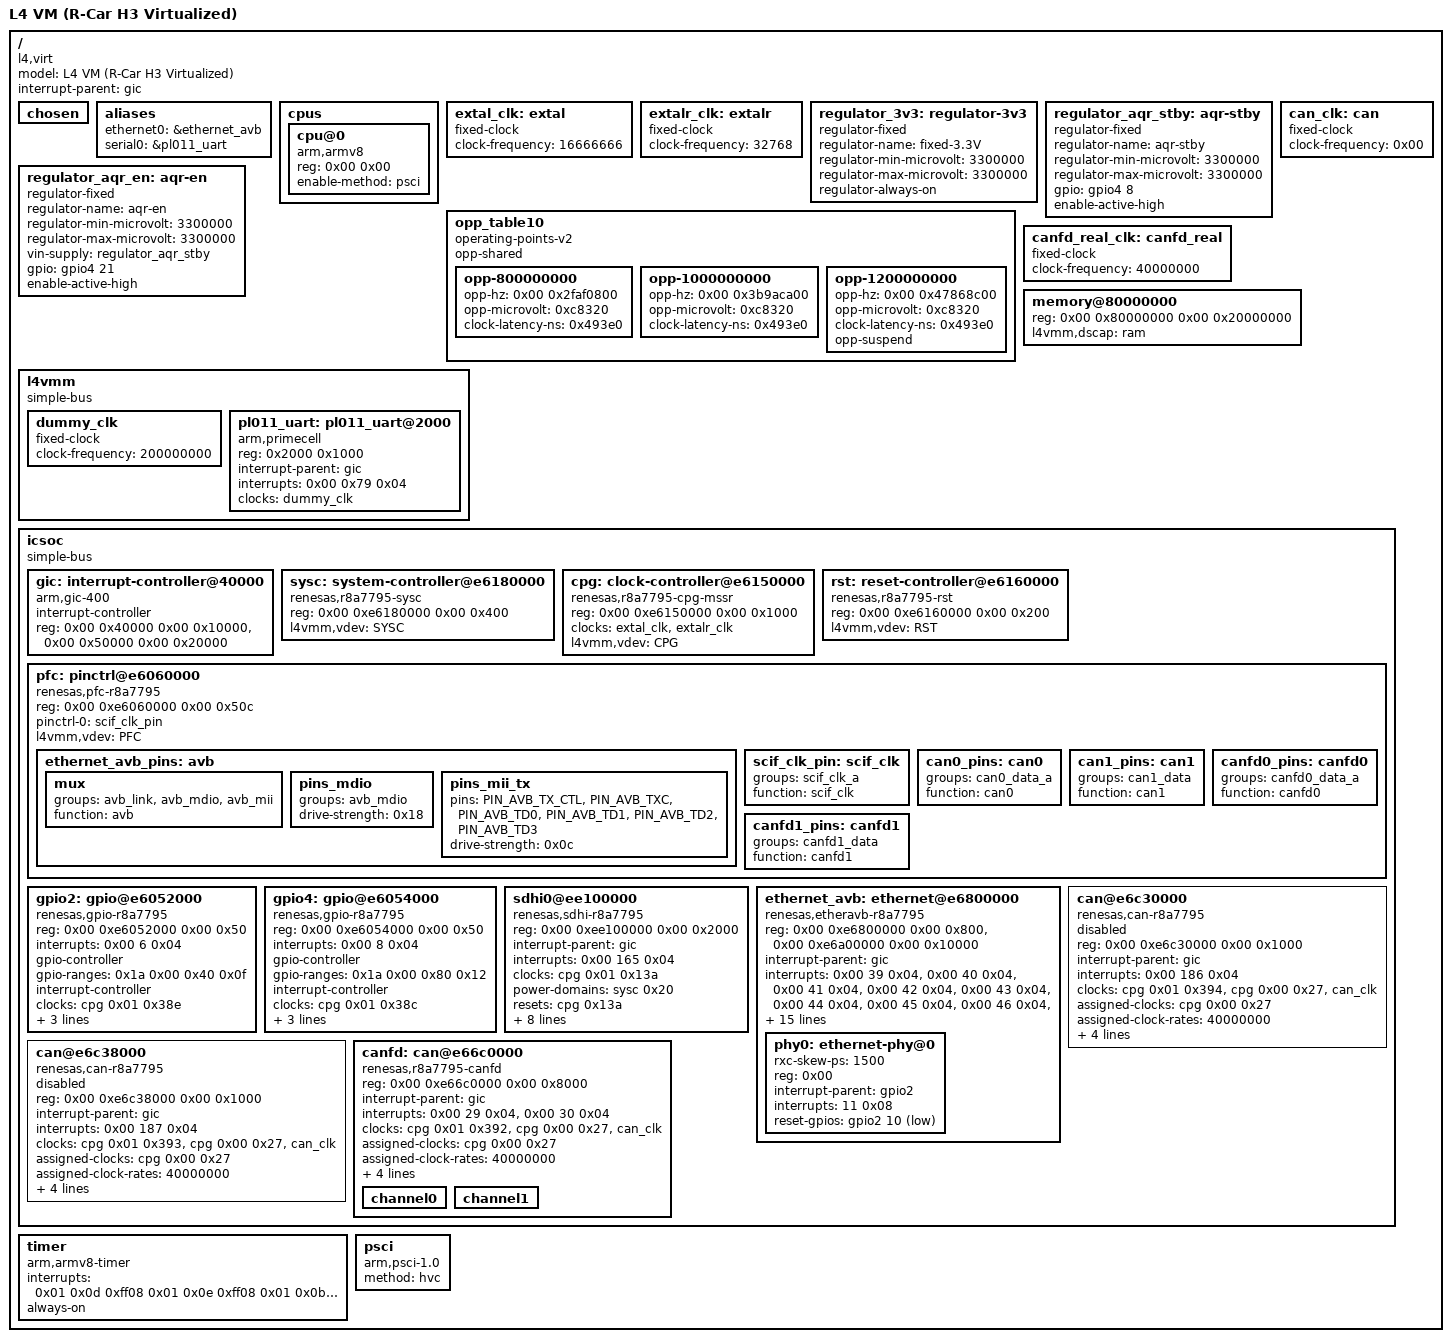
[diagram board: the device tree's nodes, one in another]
/dts-v1/;

/ {
	#address-cells = <0x02>;
	#size-cells = <0x02>;
	model = "L4 VM (R-Car H3 Virtualized)";
	/* CRITICAL: Added native R-Car strings so Renesas drivers load their pin tables */
	compatible = "l4,virt", "linux,dummy-virt", "shimafuji,kingfisher", "renesas,h3ulcb", "renesas,r8a7795";
	interrupt-parent = <&gic>;

	chosen {};
	aliases {
		ethernet0 = &ethernet_avb;
		serial0 = &pl011_uart;
	};

	cpus {
		#address-cells = <0x02>;
		#size-cells = <0x00>;
		cpu@0 {
			device_type = "cpu";
			compatible = "arm,armv8";
			reg = <0x00 0x00>;
			enable-method = "psci";
		};
	};

	/* Fixed Reference Board Clocks */
	extal_clk: extal {
		compatible = "fixed-clock";
		#clock-cells = <0x00>;
		clock-frequency = <16666666>;
		phandle = <0x1d>;
	};

	extalr_clk: extalr {
		compatible = "fixed-clock";
		#clock-cells = <0x00>;
		clock-frequency = <32768>;
		phandle = <0x1e>;
	};

	/* Fixed Power Rails */
	regulator_3v3: regulator-3v3 {
		compatible = "regulator-fixed";
		regulator-name = "fixed-3.3V";
		regulator-min-microvolt = <3300000>;
		regulator-max-microvolt = <3300000>;
		regulator-always-on;
		phandle = <0x9e>;
	};

	regulator_aqr_stby: aqr-stby {
		compatible = "regulator-fixed";
		regulator-name = "aqr-stby";
		regulator-min-microvolt = <3300000>;
		regulator-max-microvolt = <3300000>;
		gpio = <&gpio4 8 0>;
		enable-active-high;
		phandle = <0xa5>;
	};

	regulator_aqr_en: aqr-en {
		compatible = "regulator-fixed";
		regulator-name = "aqr-en";
		regulator-min-microvolt = <3300000>;
		regulator-max-microvolt = <3300000>;
		vin-supply = <&regulator_aqr_stby>;
		gpio = <&gpio4 21 0>;
		enable-active-high;
		phandle = <0x96>;
	};

	/* Target Operating Point Performance Profiles */
	opp_table10: opp_table10 {
		compatible = "operating-points-v2";
		opp-shared;
		phandle = <0x18>;

		opp-800000000 {
			opp-hz = <0x00 0x2faf0800>;
			opp-microvolt = <0xc8320>;
			clock-latency-ns = <0x493e0>;
		};
		opp-1000000000 {
			opp-hz = <0x00 0x3b9aca00>;
			opp-microvolt = <0xc8320>;
			clock-latency-ns = <0x493e0>;
		};
		opp-1200000000 {
			opp-hz = <0x00 0x47868c00>;
			opp-microvolt = <0xc8320>;
			clock-latency-ns = <0x493e0>;
			opp-suspend;
		};
	};

	/* Add this new node to explicitly tell Linux the true hardware speed */
	canfd_real_clk: canfd_real {
		compatible = "fixed-clock";
		#clock-cells = <0x00>;
		clock-frequency = <40000000>; 
	};

	/* CAN External Reference Clock */
	can_clk: can {
		compatible = "fixed-clock";
		#clock-cells = <0x00>;
		clock-frequency = <0x00>; 
		phandle = <0x56>;
	};

	/* Virtual Subsystem Simple Bus */
	l4vmm {
		#address-cells = <0x01>;
		#size-cells = <0x01>;
		compatible = "simple-bus";
		ranges = <0x00000000 0x00 0x00000000 0xffffffff>;

		dummy_clk: dummy_clk {
			compatible = "fixed-clock";
			#clock-cells = <0x00>;
			clock-frequency = <200000000>;
		};

		pl011_uart: pl011_uart@2000 {
			compatible = "arm,primecell", "arm,pl011";
			reg = <0x2000 0x1000>;
			interrupt-parent = <&gic>;
			interrupts = <0x00 0x79 0x04>;
			clocks = <&dummy_clk>;
			clock-names = "apb_pclk";
			status = "okay";
		};
	};

	memory@80000000 {
		device_type = "memory";
		reg = <0x00 0x80000000 0x00 0x20000000>;
		l4vmm,dscap = "ram";
	};

	/* Physical SoC Mapping Simple Bus */
	icsoc {
		compatible = "simple-bus";
		#address-cells = <0x02>;
		#size-cells = <0x02>;
		ranges;

		gic: interrupt-controller@40000 {
			compatible = "arm,gic-400";
			#interrupt-cells = <0x03>;
			#address-cells = <0x00>;
			interrupt-controller;
			reg = <0x00 0x40000 0x00 0x10000>, <0x00 0x50000 0x00 0x20000>;
			phandle = <0x01>;
		};

		sysc: system-controller@e6180000 {
			compatible = "renesas,r8a7795-sysc";
			reg = <0x00 0xe6180000 0x00 0x400>;
			#power-domain-cells = <0x01>;
			l4vmm,vdev = "SYSC";
			phandle = <0x09>;
		};

		cpg: clock-controller@e6150000 {
			compatible = "renesas,r8a7795-cpg-mssr";
			reg = <0x00 0xe6150000 0x00 0x1000>;
			clocks = <&extal_clk>, <&extalr_clk>;
			clock-names = "extal", "extalr";
			#clock-cells = <0x02>;
			#power-domain-cells = <0x00>;
			#reset-cells = <0x01>;
			l4vmm,vdev = "CPG";
			phandle = <0x0c>;
		};

		rst: reset-controller@e6160000 {
			compatible = "renesas,r8a7795-rst";
			reg = <0x00 0xe6160000 0x00 0x200>;
			#reset-cells = <0x01>;
			l4vmm,vdev = "RST";
		};

		/* 1:1 Passthrough for the Pin Function Controller Hardware Region */
		pfc: pinctrl@e6060000 {
			compatible = "renesas,pfc-r8a7795";
			reg = <0x00 0xe6060000 0x00 0x50c>;
			pinctrl-names = "default";
			pinctrl-0 = <&scif_clk_pin>;
			l4vmm,vdev = "PFC";
			phandle = <0x1a>;

			ethernet_avb_pins: avb {
				phandle = <0x53>;
				mux {
					groups = "avb_link", "avb_mdio", "avb_mii";
					function = "avb";
				};
				pins_mdio {
					groups = "avb_mdio";
					drive-strength = <0x18>;
				};
				pins_mii_tx {
					pins = "PIN_AVB_TX_CTL", "PIN_AVB_TXC", "PIN_AVB_TD0", "PIN_AVB_TD1", "PIN_AVB_TD2", "PIN_AVB_TD3";
					drive-strength = <0x0c>;
				};
			};

			scif_clk_pin: scif_clk {
				groups = "scif_clk_a";
				function = "scif_clk";
				phandle = <0x1b>;
			};

			can0_pins: can0 {
				groups = "can0_data_a";
				function = "can0";
				phandle = <0x57>;
			};

			can1_pins: can1 {
				groups = "can1_data";
				function = "can1";
				phandle = <0x58>;
			};

			canfd0_pins: canfd0 {
				groups = "canfd0_data_a";
				function = "canfd0";
				phandle = <0x59>;
			};

			canfd1_pins: canfd1 {
				groups = "canfd1_data";
				function = "canfd1";
				phandle = <0x5a>;
			};
		};

		gpio2: gpio@e6052000 {
			compatible = "renesas,gpio-r8a7795", "renesas,rcar-gen3-gpio";
			reg = <0x00 0xe6052000 0x00 0x50>;
			interrupts = <0x00 6 0x04>;
			#gpio-cells = <0x02>;
			gpio-controller;
			gpio-ranges = <0x1a 0x00 0x40 0x0f>;
			#interrupt-cells = <0x02>;
			interrupt-controller;
			clocks = <&cpg 0x01 0x38e>;
			power-domains = <&sysc 0x20>;
			resets = <&cpg 0x38e>;
			l4vmm,vdev = "GPIO2";
			phandle = <0x55>;
		};

		gpio4: gpio@e6054000 {
			compatible = "renesas,gpio-r8a7795", "renesas,rcar-gen3-gpio";
			reg = <0x00 0xe6054000 0x00 0x50>;
			interrupts = <0x00 8 0x04>;
			#gpio-cells = <0x02>;
			gpio-controller;
			gpio-ranges = <0x1a 0x00 0x80 0x12>;
			#interrupt-cells = <0x02>;
			interrupt-controller;
			clocks = <&cpg 0x01 0x38c>;
			power-domains = <&sysc 0x20>;
			resets = <&cpg 0x38c>;
			l4vmm,vdev = "GPIO4";
			phandle = <0x36>;
		};

		sdhi0@ee100000 {
			compatible = "renesas,sdhi-r8a7795", "renesas,rcar-gen3-sdhi";
			reg = <0x00 0xee100000 0x00 0x2000>;
			interrupt-parent = <&gic>;
			interrupts = <0x00 165 0x04>;
			clocks = <&cpg 0x01 0x13a>;
			power-domains = <&sysc 0x20>;
			resets = <&cpg 0x13a>;
			max-frequency = <200000000>;
			vmmc-supply = <&regulator_3v3>;
			vqmmc-supply = <&regulator_3v3>;
			bus-width = <4>;
			no-1-8-v;
			cap-sd-highspeed;
			non-removable;
			l4vmm,vdev = "SD_CARD";
			status = "okay";
		};

		ethernet_avb: ethernet@e6800000 {
			compatible = "renesas,etheravb-r8a7795", "renesas,etheravb-rcar-gen3";
			reg = <0x00 0xe6800000 0x00 0x800>, <0x00 0xe6a00000 0x00 0x10000>;
			reg-names = "avb_ctrl", "avb_desc";
			interrupt-parent = <&gic>;
			
			interrupts = <0x00 39 0x04>, <0x00 40 0x04>, <0x00 41 0x04>, <0x00 42 0x04>,
			             <0x00 43 0x04>, <0x00 44 0x04>, <0x00 45 0x04>, <0x00 46 0x04>,
			             <0x00 47 0x04>, <0x00 48 0x04>, <0x00 49 0x04>, <0x00 50 0x04>,
			             <0x00 51 0x04>, <0x00 52 0x04>, <0x00 53 0x04>, <0x00 54 0x04>,
			             <0x00 55 0x04>, <0x00 56 0x04>, <0x00 57 0x04>, <0x00 58 0x04>,
			             <0x00 59 0x04>, <0x00 60 0x04>, <0x00 61 0x04>, <0x00 62 0x04>,
			             <0x00 63 0x04>;
			interrupt-names = "ch0", "ch1", "ch2", "ch3", "ch4", "ch5", "ch6", "ch7",
			                  "ch8", "ch9", "ch10", "ch11", "ch12", "ch13", "ch14", "ch15",
			                  "ch16", "ch17", "ch18", "ch19", "ch20", "ch21", "ch22", "ch23",
			                  "ch24";
			
			clocks = <&cpg 0x01 0x32c>;
			power-domains = <&sysc 0x20>;
			resets = <&cpg 0x32c>;
			phy-mode = "rgmii";
			rx-internal-delay-ps = <0x00>;
			tx-internal-delay-ps = <0x7d0>;
			
			pinctrl-names = "default";
			pinctrl-0 = <&ethernet_avb_pins>;
			
			phy-handle = <&phy0>;
			l4vmm,vdev = "ETHERNET";
			status = "okay";

			#address-cells = <0x01>;
			#size-cells = <0x00>;

			phy0: ethernet-phy@0 {
				rxc-skew-ps = <1500>;
				reg = <0x00>;
				interrupt-parent = <&gpio2>;
				interrupts = <11 0x08>;
				reset-gpios = <&gpio2 10 0x01>;
			};
		};


		can@e6c30000 {
			compatible = "renesas,can-r8a7795", "renesas,rcar-gen3-can";
			reg = <0x00 0xe6c30000 0x00 0x1000>;
			interrupt-parent = <&gic>;
			interrupts = <0x00 186 0x04>;
			clocks = <&cpg 0x01 0x394>, <&cpg 0x00 0x27>, <&can_clk>;
			clock-names = "clkp1", "clkp2", "can_clk";
			assigned-clocks = <&cpg 0x00 0x27>;
			assigned-clock-rates = <40000000>; /* 0x2625a00 */
			power-domains = <&sysc 0x20>;
			resets = <&cpg 0x394>;
			status = "disabled";
			pinctrl-0 = <&can0_pins>;
			pinctrl-names = "default";
			l4vmm,vdev = "CAN0";
		};

		can@e6c38000 {
			compatible = "renesas,can-r8a7795", "renesas,rcar-gen3-can";
			reg = <0x00 0xe6c38000 0x00 0x1000>;
			interrupt-parent = <&gic>;
			interrupts = <0x00 187 0x04>;
			clocks = <&cpg 0x01 0x393>, <&cpg 0x00 0x27>, <&can_clk>;
			clock-names = "clkp1", "clkp2", "can_clk";
			assigned-clocks = <&cpg 0x00 0x27>;
			assigned-clock-rates = <40000000>; /* 0x2625a00 */
			power-domains = <&sysc 0x20>;
			resets = <&cpg 0x393>;
			status = "disabled";
			pinctrl-0 = <&can1_pins>;
			pinctrl-names = "default";
			l4vmm,vdev = "CAN1";
		};

		canfd: can@e66c0000 {
			compatible = "renesas,r8a7795-canfd", "renesas,rcar-gen3-canfd";
			reg = <0x00 0xe66c0000 0x00 0x8000>;
			interrupt-parent = <&gic>;
			interrupts = <0x00 29 0x04>, <0x00 30 0x04>;
			clocks = <&cpg 0x01 0x392>, <&cpg 0x00 0x27>, <&can_clk>;
			clock-names = "fck", "canfd", "can_clk";
			assigned-clocks = <&cpg 0x00 0x27>;
			assigned-clock-rates = <40000000>; /* 0x2625a00 */
			power-domains = <&sysc 0x20>;
			resets = <&cpg 0x392>;
			status = "okay";
			pinctrl-0 = <&canfd0_pins>, <&canfd1_pins>;
			pinctrl-names = "default";
			l4vmm,vdev = "CANFD";

			channel0 {
				status = "okay";
			};

			channel1 {
				status = "okay";
			};
		};
	};

	timer {
		compatible = "arm,armv8-timer";
		interrupts = <0x01 0x0d 0xff08 0x01 0x0e 0xff08 0x01 0x0b 0xff08 0x01 0x0a 0xff08>;
		always-on;
	};

	psci {
		compatible = "arm,psci-1.0";
		method = "hvc";
	};
};
